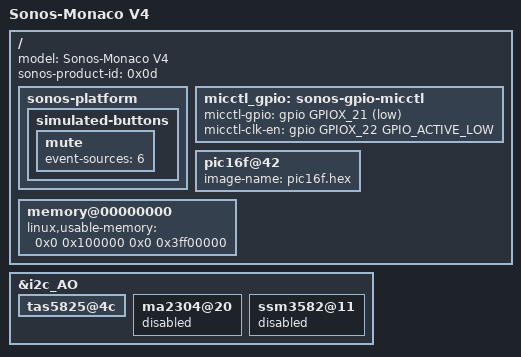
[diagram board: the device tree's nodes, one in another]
/*
 * Copyright (c) 2019-2021, Sonos, Inc.
 *
 * SPDX-License-Identifier:     GPL-2.0
 */
/* Monaco HW versions
 *      V4 - monaco.dts			- Monaco pre-DVT - GPIO changes to PIC
 */
/dts-v1/;

#include "monaco_common.dtsi"

/ {
	model = "Sonos-Monaco V4";

	sonos-product-id = <0x0d>;

	sonos-platform {
		simulated-buttons {
                        mute {
                                event-sources = <6>;
                        };
		};
	} ;

	micctl_gpio:sonos-gpio-micctl {
		micctl-gpio = <&gpio GPIOX_21 GPIO_ACTIVE_LOW>;
		micctl-clk-en = <&gpio GPIOX_22 GPIO_ACTIVE_LOW>;
	};

	pic16f@42 {
                image-name = "pic16f.hex";
	};

        memory@00000000 {
		linux,usable-memory = <0x0 0x100000 0x0 0x3ff00000>;
	};
};

/* for mic board */
&i2c_AO {
	tas5825@4c {	// Single amp, dual-channel
		status = "okay";
	};

	ma2304@20 {
		status = "disabled";
	};

	ssm3582@11 {
		status = "disabled";
	};
};
